# CORTEXM3_WKUP register map
Vendor: Texas Instruments
Peripheral module from a debugger description file (folder omap4460).
Registers are 32-bit, read-write, reset 0x0 unless marked. A register's access mark holds for its fields unless they carry their own. Offsets are as the file gives them; lines under a group give offsets from that group; [hi:lo] are bit positions; {n}, {i} and the like mark numbered series; 'fields as' and 'values as' point back to an identical list; <NAME> marks a mode.

## CORTEXM3_WKUP
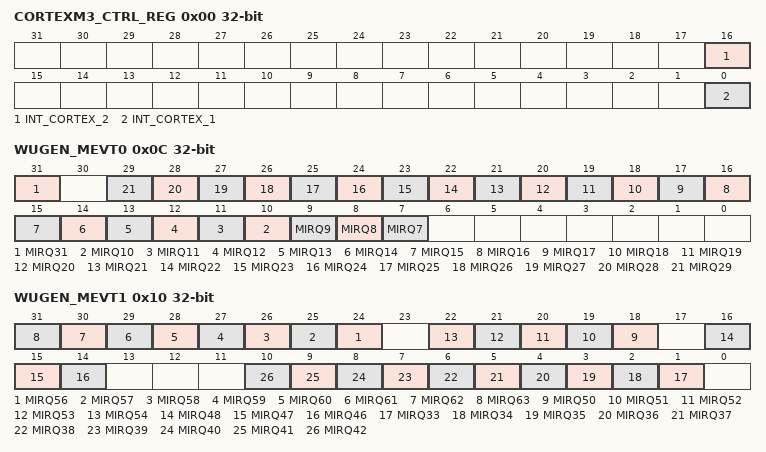
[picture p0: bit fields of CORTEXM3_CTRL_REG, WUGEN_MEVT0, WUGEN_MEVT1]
0x00 CORTEXM3_CTRL_REG — The register is used by one CPU to interrupt the other, thus used as a handshake between the two CPUs 0x0: Interrupt is cleared; 0x1: Interrupt is set.
  [16] INT_CORTEX_2 — Interrupt to ARM Cortex-M3 CPU2
  [0] INT_CORTEX_1 — Interrupt to ARM Cortex-M3 CPU1
0x04 STANDBY_CORE_SYSCONFIG reset 0x3 — Standby protocol
  [1:0] STANDBYMODE — 0x0: Force-standby mode
    1=No-standby mode; 2=Smart-standby mode; 3=Smart-standby wakeup mode - normal mode to be used
0x08 IDLE_CORE_SYSCONFIG reset 0x3 — Idle protocol
  [1:0] IDLEMODE — 0x0: Force-idle mode
    1=No-idle mode; 2=Smart-idle mode; 3=Smart-idle wakeup mode - normal mode to be used
0x0C WUGEN_MEVT0 access per field — This register contains the interrupt mask (LSB) wake-up enable bit per interrupt request 0x0: Interrupt is disabled; 0x1: Interrupt is enabled.
  [31] MIRQ31 rw — Interrupt Mask bit 31
  [n] MIRQ{n} rw (n=7..29) — Interrupt Mask bit {n}
0x10 WUGEN_MEVT1 access per field — This register contains the interrupt mask (MSB) wake-up enable bit per interrupt request 0x0: Interrupt is disabled; 0x1: Interrupt is enabled.
  [n-32] MIRQ{n} rw (n=56..63) — Interrupt Mask bit {n}
  [n-32] MIRQ{n} rw (n=50..54) — Interrupt Mask bit {n}
  [16] MIRQ48 rw — Interrupt Mask bit 48
  [15] MIRQ47 rw — Interrupt Mask bit 47
  [14] MIRQ46 rw — Interrupt Mask bit 46
  [n-32] MIRQ{n} rw (n=33..42) — Interrupt Mask bit {n}
